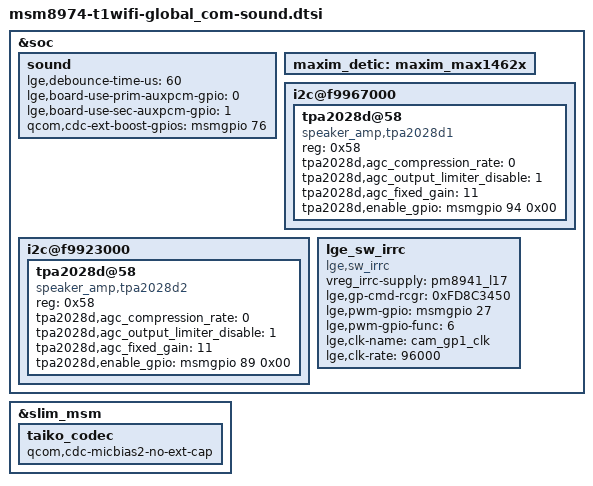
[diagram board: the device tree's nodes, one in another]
/* Copyright (c) 2013, LGE Electronics. All rights reserved.
 *
 * This program is free software; you can redistribute it and/or modify
 * it under the terms of the GNU General Public License version 2 and
 * only version 2 as published by the Free Software Foundation.
 *
 * This program is distributed in the hope that it will be useful,
 * but WITHOUT ANY WARRANTY; without even the implied warranty of
 * MERCHANTABILITY or FITNESS FOR A PARTICULAR PURPOSE.  See the
 * GNU General Public License for more details.
 */

&soc {

	sound {
		lge,debounce-time-us = <60>;
		lge,board-use-prim-auxpcm-gpio = <0>;
		lge,board-use-sec-auxpcm-gpio = <1>;

        qcom,cdc-ext-boost-gpios = <&msmgpio 76 0x00>;
	};

	maxim_detic:maxim_max1462x {
		status = "ok";		
	};

	i2c@f9967000 { /* BLSP11  R_SPE_AMP*/
		tpa2028d@58 {
			compatible = "speaker_amp,tpa2028d1";
			status = "ok";
			reg = <0x58>;
			tpa2028d,agc_compression_rate = <0>;
			tpa2028d,agc_output_limiter_disable = <1>;
			tpa2028d,agc_fixed_gain = <11>;
			tpa2028d,enable_gpio = <&msmgpio 94 0x00>;
		};
    };
    
	i2c@f9923000 {
		tpa2028d@58 { /* BLSP1  L_SPK_AMP*/
			compatible = "speaker_amp,tpa2028d2";
			status = "ok";
			reg = <0x58>;
			tpa2028d,agc_compression_rate = <0>;
			tpa2028d,agc_output_limiter_disable = <1>;
			tpa2028d,agc_fixed_gain = <11>;
			tpa2028d,enable_gpio = <&msmgpio 89 0x00>;
		};
	};

    lge_sw_irrc { /* enable SW IrRC */
        compatible = "lge,sw_irrc";
        vreg_irrc-supply = <&pm8941_l17>;
        lge,gp-cmd-rcgr = <0xFD8C3450>;
        lge,pwm-gpio = <&msmgpio 27 0x00>;
        lge,pwm-gpio-func = <6>;
        lge,clk-name = "cam_gp1_clk";
        lge,clk-rate = <96000>; //This must match with clk_freq_tbl.
    };
};

&slim_msm {

	taiko_codec {
		qcom,cdc-micbias2-no-ext-cap;
	};	

};
